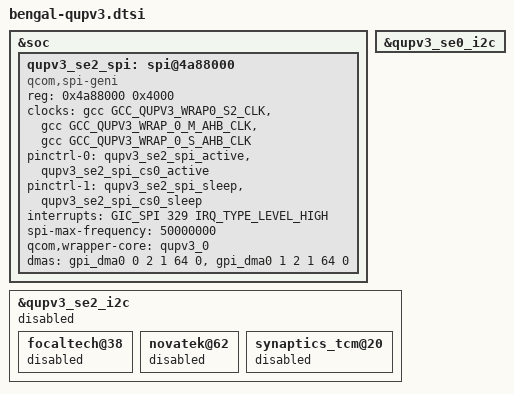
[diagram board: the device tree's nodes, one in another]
&soc {
	qupv3_se2_spi: spi@4a88000 {
		compatible = "qcom,spi-geni";
		#address-cells = <1>;
		#size-cells = <0>;
		reg = <0x4a88000 0x4000>;
		reg-names = "se_phys";
		clock-names = "se-clk", "m-ahb", "s-ahb";
		clocks = <&gcc GCC_QUPV3_WRAP0_S2_CLK>,
			<&gcc GCC_QUPV3_WRAP_0_M_AHB_CLK>,
			<&gcc GCC_QUPV3_WRAP_0_S_AHB_CLK>;
		pinctrl-names = "default", "sleep";
		pinctrl-0 = <&qupv3_se2_spi_active>, <&qupv3_se2_spi_cs0_active>;
		pinctrl-1 = <&qupv3_se2_spi_sleep>, <&qupv3_se2_spi_cs0_sleep>;
		interrupts = <GIC_SPI 329 IRQ_TYPE_LEVEL_HIGH>;
		spi-max-frequency = <50000000>;
		qcom,wrapper-core = <&qupv3_0>;
		dmas = <&gpi_dma0 0 2 1 64 0>,
			<&gpi_dma0 1 2 1 64 0>;
		dma-names = "tx", "rx";
	};
};

&qupv3_se0_i2c {
	status = "ok";
};

&qupv3_se2_i2c {
	status = "disabled";

	focaltech@38 {
		status = "disabled";
	};

	novatek@62 {
		status = "disabled";
	};

	synaptics_tcm@20 {
		status = "disabled";
	};
};
